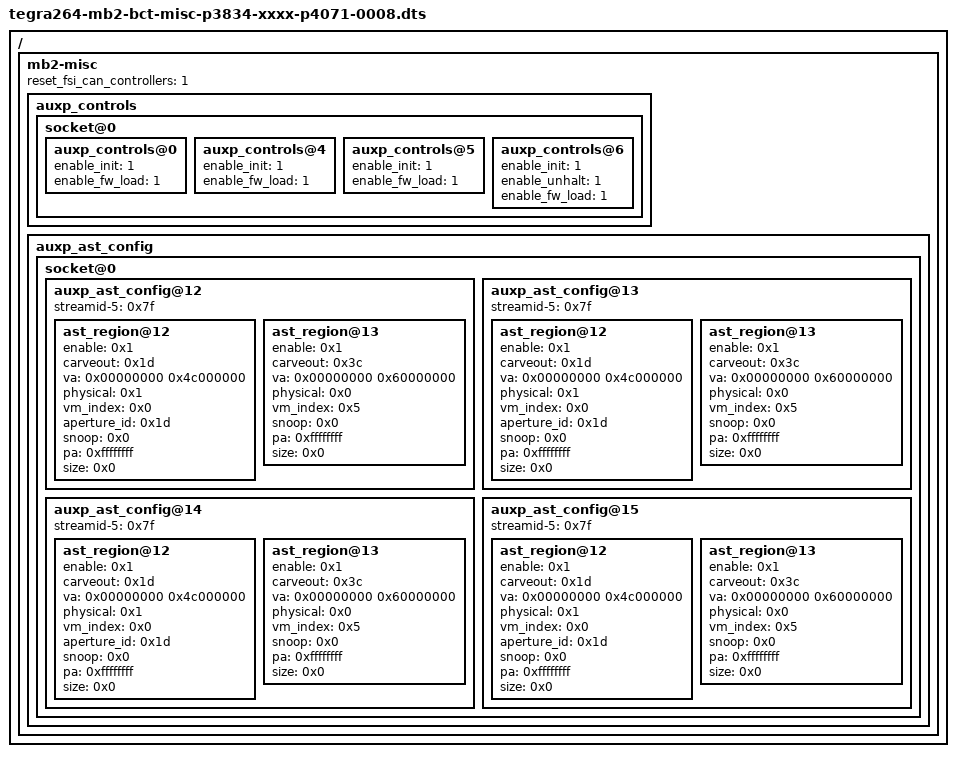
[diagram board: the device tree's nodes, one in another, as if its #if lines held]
/*
 * SPDX-FileCopyrightText: Copyright (c) 2024-2025, NVIDIA CORPORATION & AFFILIATES. All rights reserved.
 * SPDX-License-Identifier: BSD-3-Clause
 *
 * Redistribution and use in source and binary forms, with or without
 * modification, are permitted provided that the following conditions are met:
 *
 * 1. Redistributions of source code must retain the above copyright notice, this
 * list of conditions and the following disclaimer.
 *
 * 2. Redistributions in binary form must reproduce the above copyright notice,
 * this list of conditions and the following disclaimer in the documentation
 * and/or other materials provided with the distribution.
 *
 * 3. Neither the name of the copyright holder nor the names of its
 * contributors may be used to endorse or promote products derived from
 * this software without specific prior written permission.
 *
 * THIS SOFTWARE IS PROVIDED BY THE COPYRIGHT HOLDERS AND CONTRIBUTORS "AS IS"
 * AND ANY EXPRESS OR IMPLIED WARRANTIES, INCLUDING, BUT NOT LIMITED TO, THE
 * IMPLIED WARRANTIES OF MERCHANTABILITY AND FITNESS FOR A PARTICULAR PURPOSE ARE
 * DISCLAIMED. IN NO EVENT SHALL THE COPYRIGHT HOLDER OR CONTRIBUTORS BE LIABLE
 * FOR ANY DIRECT, INDIRECT, INCIDENTAL, SPECIAL, EXEMPLARY, OR CONSEQUENTIAL
 * DAMAGES (INCLUDING, BUT NOT LIMITED TO, PROCUREMENT OF SUBSTITUTE GOODS OR
 * SERVICES; LOSS OF USE, DATA, OR PROFITS; OR BUSINESS INTERRUPTION) HOWEVER
 * CAUSED AND ON ANY THEORY OF LIABILITY, WHETHER IN CONTRACT, STRICT LIABILITY,
 * OR TORT (INCLUDING NEGLIGENCE OR OTHERWISE) ARISING IN ANY WAY OUT OF THE USE
 * OF THIS SOFTWARE, EVEN IF ADVISED OF THE POSSIBILITY OF SUCH DAMAGE.
 */
/*
# CFG Version 1.0
# This File contains the configuration of multiple rails.
*/
/dts-v1/;

#ifdef AUTO_BUILD
#include "tegrabl_carveout_id.h"
#else
#include "t264_tegrabl_carveout_id.h"
#endif

#include "tegra264-mb2-bct-common.dtsi"
/ {
    mb2-misc {
        /*
         * When FSI enable_unhalt= <1>, reset_fsi_can_controllers field will
         * be ignored.
         * When FSI enable_unhalt = <0> and reset_fsi_can_controllers = <1>,
         * FSI CAN will reset
         */
        reset_fsi_can_controllers = <1>;

        auxp_controls {
            socket@0 {
                /* Control fields for AON cluster. */
                auxp_controls@0 {
                    enable_init = <1>;
                    enable_fw_load = <1>;
                };

                /* Control fields for APE cluster. */
                auxp_controls@4 {
                    enable_init = <1>;
                    enable_fw_load = <1>;
                };

                /* Control fields for APE1 cluster. */
                auxp_controls@5 {
                    enable_init = <1>;
                    enable_fw_load = <1>;
                };

                /* Control fields for FSI cluster. */
                auxp_controls@6 {
                    enable_init = <1>;
                    enable_unhalt = <1>;
                    enable_fw_load = <1>;
                };
            };
        };

        auxp_ast_config {
            socket@0 {
                /* AST_FSI_CPU0_AXIM */
                auxp_ast_config@12 {
                   streamid-5 = <0x7f>;
                    /* GPCDMA Test in FSI */
                   ast_region@12 {
                        enable = <0x1>;
                        /* GSC29(FSI) carveout for FSI FW in DRAM */
                        carveout = <0x1d>;
                        va = <0x00000000 0x4c000000>;
                        /* bypass SMMU */
                        physical = <0x1>;
                        /* use bypass StreamID*/
                        vm_index = <0x0>;
                        aperture_id = <0x1d>;
                        snoop = <0x0>;
                        /* pa and size used is as configured by mb2 */
                        pa = <0xffffffff>;
                        size = <0x0>;
                    };
                    /*AST config for DRAM ECC error injection carveout */
                    ast_region@13 {
                        enable = <0x1>;
                        /* CARVEOUT_DRAM_ECC_TEST */
                        carveout = <0x3c>;
                        va = <0x00000000 0x60000000>;
                        physical = <0x0>;
                        vm_index = <0x5>;
                        snoop = <0x0>;
                        pa = <0xffffffff>;
                        size = <0x0>;
                    };
                };
                /* AST_FSI_CPU1_AXIM */
                auxp_ast_config@13 {
                   streamid-5 = <0x7f>;
                    /* GPCDMA Test in FSI */
                   ast_region@12 {
                        enable = <0x1>;
                        /* GSC29(FSI) carveout for FSI FW in DRAM */
                        carveout = <0x1d>;
                        va = <0x00000000 0x4c000000>;
                        /* bypass SMMU */
                        physical = <0x1>;
                        /* use bypass StreamID*/
                        vm_index = <0x0>;
                        aperture_id = <0x1d>;
                        snoop = <0x0>;
                        /* pa and size used is as configured by mb2 */
                        pa = <0xffffffff>;
                        size = <0x0>;
                    };
                    /*AST config for DRAM ECC error injection carveout */
                    ast_region@13 {
                        enable = <0x1>;
                        /* CARVEOUT_DRAM_ECC_TEST */
                        carveout = <0x3c>;
                        va = <0x00000000 0x60000000>;
                        physical = <0x0>;
                        vm_index = <0x5>;
                        snoop = <0x0>;
                        pa = <0xffffffff>;
                        size = <0x0>;
                    };
                };
                /* AST_FSI_CPU2_AXIM */
                auxp_ast_config@14 {
                   streamid-5 = <0x7f>;
                    /* GPCDMA Test in FSI */
                   ast_region@12 {
                        enable = <0x1>;
                        /* GSC29(FSI) carveout for FSI FW in DRAM */
                        carveout = <0x1d>;
                        va = <0x00000000 0x4c000000>;
                        /* bypass SMMU */
                        physical = <0x1>;
                        /* use bypass StreamID*/
                        vm_index = <0x0>;
                        aperture_id = <0x1d>;
                        snoop = <0x0>;
                        /* pa and size used is as configured by mb2 */
                        pa = <0xffffffff>;
                        size = <0x0>;
                    };
                    /*AST config for DRAM ECC error injection carveout */
                    ast_region@13 {
                        enable = <0x1>;
                        /* CARVEOUT_DRAM_ECC_TEST */
                        carveout = <0x3c>;
                        va = <0x00000000 0x60000000>;
                        physical = <0x0>;
                        vm_index = <0x5>;
                        snoop = <0x0>;
                        pa = <0xffffffff>;
                        size = <0x0>;
                    };
                };
                /* AST_FSI_CPU3_AXIM */
                auxp_ast_config@15 {
                   streamid-5 = <0x7f>;
                    /* GPCDMA Test in FSI */
                   ast_region@12 {
                        enable = <0x1>;
                        /* GSC29(FSI) carveout for FSI FW in DRAM */
                        carveout = <0x1d>;
                        va = <0x00000000 0x4c000000>;
                        /* bypass SMMU */
                        physical = <0x1>;
                        /* use bypass StreamID*/
                        vm_index = <0x0>;
                        aperture_id = <0x1d>;
                        snoop = <0x0>;
                        /* pa and size used is as configured by mb2 */
                        pa = <0xffffffff>;
                        size = <0x0>;
                    };
                    /*AST config for DRAM ECC error injection carveout */
                    ast_region@13 {
                        enable = <0x1>;
                        /* CARVEOUT_DRAM_ECC_TEST */
                        carveout = <0x3c>;
                        va = <0x00000000 0x60000000>;
                        physical = <0x0>;
                        vm_index = <0x5>;
                        snoop = <0x0>;
                        pa = <0xffffffff>;
                        size = <0x0>;
                    };
                };
            };
        };
    };
};

